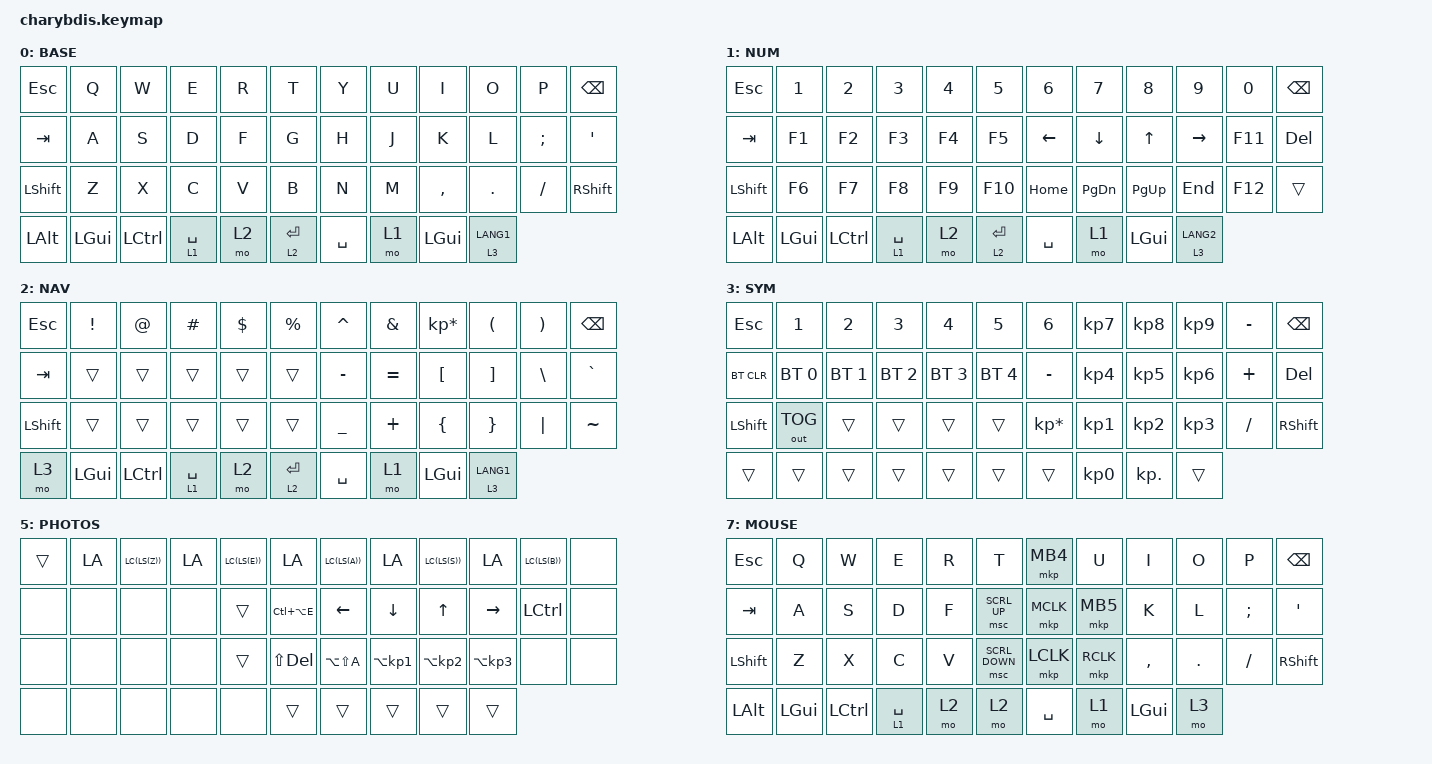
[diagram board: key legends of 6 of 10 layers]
#include <behaviors.dtsi>
#include <behaviors/mouse_move.dtsi>
//#include <behaviors/mouse_scroll.dtsi>
#include <dt-bindings/zmk/bt.h>
#include <dt-bindings/zmk/keys.h>
#include <dt-bindings/zmk/mouse.h>
//#include <dt-bindings/zmk/pointing.h>
#include <dt-bindings/zmk/outputs.h>
#include <behaviors/mouse_keys.dtsi>
#include <dt-bindings/zmk/ext_power.h>
#include "macros.dtsi"
#include "behaviors.dtsi"
#include "combos.dtsi"



//#define ZMK_MOUSE_SCRL_VAL 140
// mouse.h 중복으로 아래 주석처리함
//#define ZMK_MOUSE_DEFAULT_SCRL_VAL 100
#define ZMK_POINTING_DEFAULT_SCRL_VAL 130

/ {
    /* input config for mouse move mode */
    trackball_listener {
        compatible = "zmk,input-behavior-listener";
        device = <&vtrackball>;
        layers = <0 1 7>;
        evt-type = <INPUT_EV_REL>;
        x-input-code = <INPUT_REL_X>;
        y-input-code = <INPUT_REL_Y>;
        scale-multiplier = <4>;
        scale-divisor = <5>;
         bindings = <&ib_toggle_layer 7>;
    };

    /* input config for snipe mode */
    trackball_snipe_listener {
        compatible = "zmk,input-behavior-listener";   
        device = <&vtrackball>;
        layers = <8>;
        evt-type = <INPUT_EV_REL>;
        x-input-code = <INPUT_REL_X>;
        y-input-code = <INPUT_REL_Y>;
        scale-multiplier = <1>;
        scale-divisor = <6>;
    };

    /* input config for mouse scroll mode */
    trackball_scroll_listener {
        compatible = "zmk,input-behavior-listener";
        device = <&vtrackball>;
        layers = <2>;
        evt-type = <INPUT_EV_REL>;            
        x-input-code = <INPUT_REL_MISC>;
        y-input-code = <INPUT_REL_WHEEL>;
        y-invert;
        bindings = <&ib_wheel_scaler 1 14>;
    };

    /* define a resolution down scaler only for INPUT_REL_WHEEL */
    ib_wheel_scaler: ib_wheel_scaler {
        compatible = "zmk,input-behavior-scaler";
        #binding-cells = <2>;
        evt-type = <INPUT_EV_REL>;
        input-code = <INPUT_REL_WHEEL>;
    };

    /* adjust cooldown waiting period for mouse key layer after activated */
    ib_toggle_layer: ib_toggle_layer {
        compatible = "zmk,input-behavior-tog-layer";
        #binding-cells = <1>;
        time-to-live-ms = <850>;
    };
// ╭──────┬──────┬──────┬──────┬──────┬──────╮  ╭──────┬──────┬──────┬──────┬──────┬──────╮
//    00     01     02     03    04      05        06     07     08     09     10     11
// ├──────┼──────┼──────┼──────┼──────┼──────┤  ├──────┼──────┼──────┼──────┼──────┼──────┤
//    12     13     14     15    16      17        18     19     20     21     22     23
// ├──────┼──────┼──────┼──────┼──────┼──────┤  ├──────┼──────┼──────┼──────┼──────┼──────┤
//    24     25     26     27    28      29        30     31     32     33     34     35
// ╰──────┴──────┴──────┼──────┼──────┼──────┤  ├──────┼──────┼──────┴──────┴──────┴──────╯
//                         36     37     38        39     40
//                      ╰──────┴──────┴──────╯  ╰──────┴──────╯
// #define BASE    0
// #define NUM     1
// #define NAV     2
// #define SYM     3
// #define GAME    4
// #define PHOTOS  5
// #define EXTRAS  6
// #define MOUSE   7
// #define SLOW    8
// #define SCROLL  9
     
	scroll_up_down: behavior_sensor_rotate_mouse_wheel_up_down {
		compatible = "zmk,behavior-sensor-rotate";
		#sensor-binding-cells = <0>;
		tap-ms = <30>;
		//bindings = <&inc_dec_kp C_VOLUME_UP>,<&inc_dec_kp C_VOLUME_DOWN>;  // 에러남
        	bindings = <&msc SCRL_UP>, <&msc SCRL_DOWN>;
        	//bindings = <&kp PG_UP>, <&kp PG_DN>;  //잘 작동함
	};

	keymap {
        compatible = "zmk,keymap";
        BASE {
            sensor-bindings = <&scroll_up_down>;
	    //sensor-bindings = <&inc_dec_kp UP DOWN>;   // 위아래로 한칸식 화살표로 이동한것과 같은 키 마우스 키가 안됨 
	    //sensor-bindings = <&msc SCRL_UP SCRL_DOWN>; // 에러남
	    //sensor-bindings = <&msc SCRL_UP>, <&msc SCRL_DOWN>; //에러남

            bindings = <
  &kp ESC  &kp Q &kp W &kp E &kp R &kp T   &kp Y &kp U  &kp I  &kp O   &kp P    &kp BSPC
  &kp TAB &kp A &kp S &kp D &kp F &kp G   &kp H &kp J  &kp K     &kp L   &kp SEMI &kp SQT
  &kp LSHFT &kp Z &kp X &kp C &kp V &kp B   &kp N &kp M  &kp COMMA &kp DOT &kp FSLH &kp RSHFT
   &kp LALT  &kp LGUI  &kp LCTRL  &lt 1 SPC  &mo 2  &lt 2 RET  &kp SPC  &mo 1  &kp LGUI &lt 3 LANG1
            >;
        };

        NUM {
            //sensor-bindings = <&scroll_up_down>;
	    sensor-bindings = <&inc_dec_kp UP DOWN>;
	    //sensor-bindings = <&inc_dec_kp C_FF C_RW>;  //미디어 빨리감 되감기 잘안됨
            bindings = <
   &kp ESC    &kp N1     &kp N2       &kp N3       &kp N4       &kp N5         &kp N6    &kp N7    &kp N8     &kp N9      &kp N0  &kp BSPC
   &kp TAB    &kp F1     &kp F2       &kp F3       &kp F4       &kp F5         &kp LEFT  &kp DOWN  &kp UP     &kp RIGHT   &kp F11 &kp DEL
   &kp LSHFT  &kp F6     &kp F7       &kp F8       &kp F9       &kp F10        &kp HOME  &kp PG_DN &kp PG_UP  &kp END     &kp F12 &trans
   &kp LALT  &kp LGUI  &kp LCTRL  &lt 1 SPC  &mo 2  &lt 2 RET  &kp SPC  &mo 1   &kp LGUI  &lt 3 LANG2
            >;
        };

        NAV {
		sensor-bindings = <&inc_dec_kp C_VOLUME_UP C_VOLUME_DOWN>;
		bindings = <
   &kp ESC  &kp EXCL &kp AT &kp HASH &kp DLLR &kp PRCNT   &kp CARET &kp AMPS  &kp KP_MULTIPLY &kp LPAR &kp RPAR &kp BSPC
   &kp TAB  &trans   &trans &trans   &trans   &trans      &kp MINUS &kp EQUAL &kp LBKT        &kp RBKT &kp BSLH &kp GRAVE
   &kp LSHFT &trans   &trans &trans   &trans   &trans      &kp UNDER &kp PLUS  &kp LBRC        &kp RBRC &kp PIPE &kp TILDE
      &mo 3  &kp LGUI  &kp LCTRL  &lt 1 SPC &mo 2  &lt 2 RET  &kp SPC  &mo 1  &kp LGUI  &lt 3 LANG1
            >;
        };

        SYM {
            bindings = <
   &kp ESC    &kp N1       &kp N2       &kp N3       &kp N4       &kp N5         &kp N6           &kp KP_N7  &kp KP_N8  &kp KP_N9  &kp MINUS  &kp BSPC
   &bt BT_CLR &bt BT_SEL 0 &bt BT_SEL 1 &bt BT_SEL 2 &bt BT_SEL 3 &bt BT_SEL 4   &kp MINUS        &kp KP_N4  &kp KP_N5  &kp KP_N6  &kp PLUS  &kp DEL
   &kp LSHFT   &out OUT_TOG   &trans       &trans       &trans       &trans      &kp KP_MULTIPLY  &kp KP_N1  &kp KP_N2  &kp KP_N3  &kp FSLH  &kp RSHFT
     &trans   &trans      &trans     &trans       &trans      &trans  &trans                     &kp KP_N0             &kp KP_DOT   &trans
            >;
        };

        GAME {
            bindings = <
&kp N1  &kp TAB    &kp Q  &kp W   &kp E      &kp R           &none  &none  &none  &none  &none  &trans
&kp N2  &kp LCTRL  &kp A  &kp S   &kp D      &kp F           &none  &none  &none  &none  &none  &none
&kp N3  &kp LSHFT  &kp Z  &kp X   &kp C      &kp V           &none  &none  &none  &none  &none  &none
                          &none   &kp SPACE  &kp LEFT_ALT    &none  &none
            >;
        };

        PHOTOS {
            bindings = <
&trans          &kp LA(LC(LS(Z)))  &kp LA(LC(LS(E)))  &kp LA(LC(LS(A)))  &kp LA(LC(LS(S)))  &kp LA(LC(LS(B)))    &none   &none   &none  &none  &none  &trans
&kp LC(LA(E))   &kp LEFT           &kp DOWN           &kp UP             &kp RIGHT          &kp LCTRL            &none   &none   &none  &none  &none  &trans
&kp LS(DELETE)  &kp LA(LS(A))      &kp LA(KP_N1)      &kp LA(KP_N2)      &kp LA(KP_N3)      &none                &none   &none   &none  &none  &none  &none
                                                      &trans             &trans             &trans               &trans  &trans
            >;
        };

        EXTRAS {
            bindings = <
&kp C_POWER       &shrug  &lgtm     &gcm      &none  &kp C_BRIGHTNESS_INC    &bt BT_SEL 0  &bt BT_SEL 1    &bt BT_SEL 2       &bt BT_SEL 3  &out OUT_TOG     &bt BT_CLR
&kp C_SLEEP       &sudo   &none     &none     &none  &kp C_BRIGHTNESS_DEC    &none         &kp C_PREVIOUS  &kp C_PLAY_PAUSE   &kp C_STOP    &kp C_NEXT       &none
&kp C_AL_COFFEE   &none   &none     &none     &none  &none                   &new_dir      &kp K_MUTE      &kp C_VOLUME_DOWN  &kp C_VOLUME_UP   &kp PRINTSCREEN  &studio_unlock
                                    &none     &none  &none                   &none         &none
            >;
        };

        MOUSE {
            sensor-bindings = <&scroll_up_down>;
            bindings = <
   &kp ESC  &kp Q &kp W &kp E &kp R &kp T    &mkp MB4 &kp U  &kp I  &kp O   &kp P    &kp BSPC
   &kp TAB &kp A &kp S &kp D &kp F &msc SCRL_UP     &mkp MCLK &mkp MB5  &kp K     &kp L   &kp SEMI &kp SQT
   &kp LSHFT &kp Z &kp X &kp C &kp V &msc SCRL_DOWN  &mkp LCLK &mkp RCLK  &kp COMMA &kp DOT &kp FSLH &kp RSHFT
   &kp LALT  &kp LGUI  &kp LCTRL  &lt 1 SPC  &mo 2  &mo 2  &kp SPC  &mo 1 &kp LGUI   &mo 3 
            >;
        };

        SLOW {
            bindings = <
&trans    &trans    &trans    &trans    &trans    &trans    &trans    &trans    &trans    &trans    &trans    &trans
&trans    &trans    &trans    &trans    &trans    &trans    &trans    &trans    &trans    &trans    &trans    &trans
&trans    &trans    &trans    &trans    &trans    &trans    &trans    &trans    &trans    &trans    &trans    &trans
                              &trans    &trans    &trans    &trans    &trans
            >;
        };

        SCROLL {
            bindings = <
&trans    &trans    &trans    &trans    &trans    &trans    &trans    &trans    &trans    &trans    &trans    &trans
&trans    &trans    &trans    &trans    &trans    &trans    &trans    &trans    &trans    &trans    &trans    &trans
&trans    &trans    &trans    &trans    &trans    &trans    &trans    &trans    &trans    &trans    &trans    &trans
                              &trans    &trans    &trans    &trans    &trans
            >;
        };
    };
};
